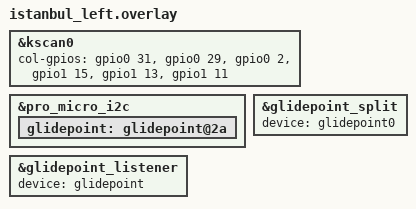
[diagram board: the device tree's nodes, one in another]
/*
 * Copyright (c) 2025 The ZMK Contributors
 *
 * SPDX-License-Identifier: MIT
 */


#include "istanbul.dtsi"
#include "shared.dtsi"


&kscan0 {
    col-gpios
        = <&gpio0 31 GPIO_ACTIVE_HIGH> // col1
        , <&gpio0 29 GPIO_ACTIVE_HIGH>  // col2
        , <&gpio0 2  GPIO_ACTIVE_HIGH>   // col3
        , <&gpio1 15 GPIO_ACTIVE_HIGH> // col4
        , <&gpio1 13 GPIO_ACTIVE_HIGH>  // col5
        , <&gpio1 11 GPIO_ACTIVE_HIGH>  // col6
        ;
};






&pro_micro_i2c {
    status = "okay";

    glidepoint: glidepoint@2a {
        status = "okay";
    };
};

// Overrides for the input listener node
&glidepoint_listener {
    status = "okay";
    device = <&glidepoint>;
};


&glidepoint_split {
    device = <&glidepoint0>;
};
